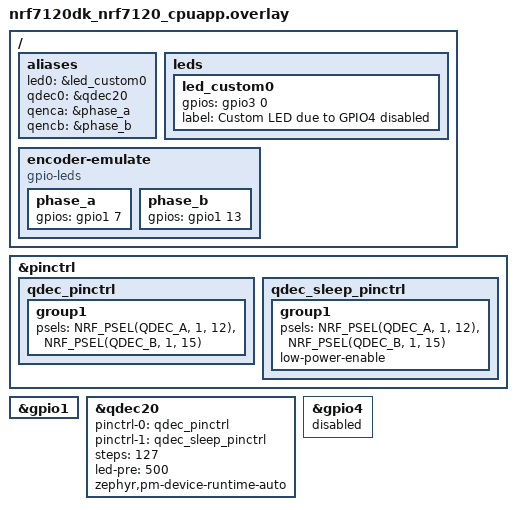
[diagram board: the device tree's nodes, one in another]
/*
 * Copyright (c) 2026 Nordic Semiconductor ASA
 *
 * SPDX-License-Identifier: LicenseRef-Nordic-5-Clause
 */

/*
 * Required loopbacks:
 * P1.07 - P1.12
 * P1.13 - P1.15
 */

/ {
	aliases {
		led0 = &led_custom0;
		qdec0 = &qdec20;
		qenca = &phase_a;
		qencb = &phase_b;
	};

	leds {
		led_custom0: led_custom0 {
			gpios = <&gpio3 0 GPIO_ACTIVE_HIGH>;
			label = "Custom LED due to GPIO4 disabled";
		};
	};

	encoder-emulate {
		compatible = "gpio-leds";

		phase_a: phase_a {
			gpios = <&gpio1 7 GPIO_ACTIVE_HIGH>;
		};

		phase_b: phase_b {
			gpios = <&gpio1 13 GPIO_ACTIVE_HIGH>;
		};
	};
};

&pinctrl {
	qdec_pinctrl: qdec_pinctrl {
		group1 {
			psels = <NRF_PSEL(QDEC_A, 1, 12)>,
				<NRF_PSEL(QDEC_B, 1, 15)>;
		};
	};

	qdec_sleep_pinctrl: qdec_sleep_pinctrl {
		group1 {
			psels = <NRF_PSEL(QDEC_A, 1, 12)>,
				<NRF_PSEL(QDEC_B, 1, 15)>;
			low-power-enable;
		};
	};
};

&gpio1 {
	status = "okay";
};

&qdec20 {
	status = "okay";
	pinctrl-0 = <&qdec_pinctrl>;
	pinctrl-1 = <&qdec_sleep_pinctrl>;
	pinctrl-names = "default", "sleep";
	steps = <127>;
	led-pre = <500>;
	zephyr,pm-device-runtime-auto;
};

&gpio4 {
	status = "disabled";
};
